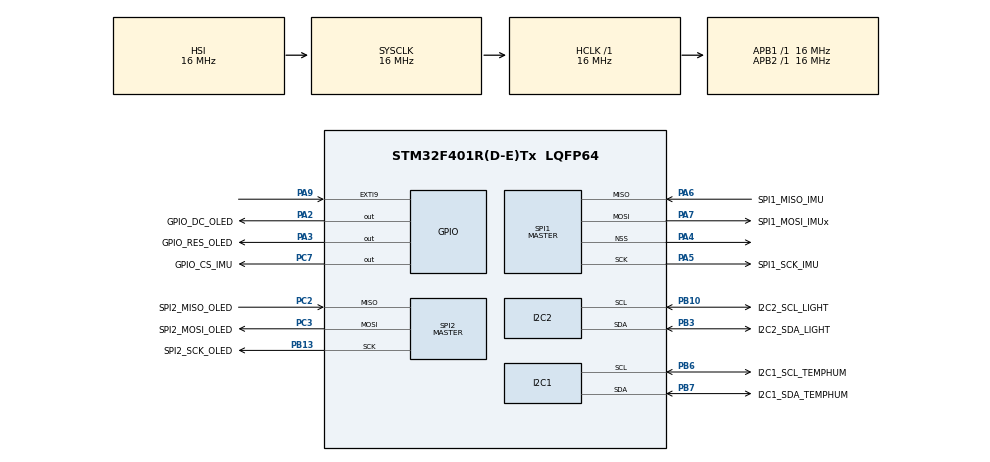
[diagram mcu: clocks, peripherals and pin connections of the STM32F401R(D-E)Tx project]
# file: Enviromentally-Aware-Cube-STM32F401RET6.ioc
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FREERTOS.Tasks01=defaultTask,24,128,StartDefaultTask,Default,NULL,Dynamic,NULL,NULL
Mcu.Family=STM32F4
Mcu.Name=STM32F401R(D-E)Tx
Mcu.Package=LQFP64
NVIC.PriorityGroup=NVIC_PRIORITYGROUP_4
PA2.GPIO_Label=GPIO_DC_OLED
PA2.Signal=GPIO_Output
PA3.GPIO_Label=GPIO_RES_OLED
PA3.Signal=GPIO_Output
PA4.Mode=NSS_Signal_Hard_Output
PA4.Signal=SPI1_NSS
PA5.GPIO_Label=SPI1_SCK_IMU
PA5.Mode=Full_Duplex_Master
PA5.Signal=SPI1_SCK
PA6.GPIO_Label=SPI1_MISO_IMU
PA6.Mode=Full_Duplex_Master
PA6.Signal=SPI1_MISO
PA7.GPIO_Label=SPI1_MOSI_IMUx
PA7.Mode=Full_Duplex_Master
PA7.Signal=SPI1_MOSI
PA9.Signal=GPXTI9
PB10.GPIO_Label=I2C2_SCL_LIGHT
PB10.Mode=I2C
PB10.Signal=I2C2_SCL
PB13.GPIO_Label=SPI2_SCK_OLED
PB13.Mode=Full_Duplex_Master
PB13.Signal=SPI2_SCK
PB3.GPIO_Label=I2C2_SDA_LIGHT
PB3.Mode=I2C
PB3.Signal=I2C2_SDA
PB6.GPIO_Label=I2C1_SCL_TEMPHUM
PB6.Mode=I2C
PB6.Signal=I2C1_SCL
PB7.GPIO_Label=I2C1_SDA_TEMPHUM
PB7.Mode=I2C
PB7.Signal=I2C1_SDA
PC2.GPIO_Label=SPI2_MISO_OLED
PC2.Mode=Full_Duplex_Master
PC2.Signal=SPI2_MISO
PC3.GPIO_Label=SPI2_MOSI_OLED
PC3.Mode=Full_Duplex_Master
PC3.Signal=SPI2_MOSI
PC7.GPIO_Label=GPIO_CS_IMU
PC7.Signal=GPIO_Output
ProjectManager.HeapSize=0x200
ProjectManager.StackSize=0x400
ProjectManager.TargetToolchain=STM32CubeIDE
RCC.AHBFreq_Value=16000000
RCC.APB1Freq_Value=16000000
RCC.APB2Freq_Value=16000000
RCC.CortexFreq_Value=16000000
RCC.HSE_VALUE=25000000
RCC.HSI_VALUE=16000000
RCC.LSE_VALUE=32768
RCC.SYSCLKFreq_VALUE=16000000
RCC.VCOOutputFreq_Value=192000000
SPI1.Direction=SPI_DIRECTION_2LINES
SPI1.Mode=SPI_MODE_MASTER
SPI1.VirtualNSS=VM_NSSHARD
SPI1.VirtualType=VM_MASTER
SPI2.Direction=SPI_DIRECTION_2LINES
SPI2.Mode=SPI_MODE_MASTER
SPI2.VirtualType=VM_MASTER
VP_FREERTOS_VS_CMSIS_V2.Mode=CMSIS_V2
board=custom

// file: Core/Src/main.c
/* USER CODE BEGIN Header */
/**
  ******************************************************************************
  * @file           : main.c
  * @brief          : Main program body
  ******************************************************************************
  * @attention
  *
  * Copyright (c) 2025 STMicroelectronics.
  * All rights reserved.
  *
  * This software is licensed under terms that can be found in the LICENSE file
  * in the root directory of this software component.
  * If no LICENSE file comes with this software, it is provided AS-IS.
  *
  ******************************************************************************
  */
/* USER CODE END Header */
#include "main.h"
#include "cmsis_os.h"

/* USER CODE BEGIN Includes */
#include "oled.h"
/* USER CODE END Includes */

I2C_HandleTypeDef hi2c1;
I2C_HandleTypeDef hi2c2;

SPI_HandleTypeDef hspi1;
SPI_HandleTypeDef hspi2;

/* Definitions for defaultTask */
osThreadId_t defaultTaskHandle;
const osThreadAttr_t defaultTask_attributes = {
  .name = "defaultTask",
  .stack_size = 128 * 4,
  .priority = (osPriority_t) osPriorityNormal,
};

void SystemClock_Config(void);
static void MX_GPIO_Init(void);
static void MX_SPI1_Init(void);
static void MX_I2C1_Init(void);
static void MX_I2C2_Init(void);
static void MX_SPI2_Init(void);
void StartDefaultTask(void *argument);

int main(void)
{

  /* MCU Configuration--------------------------------------------------------*/

  /* Reset of all peripherals, Initializes the Flash interface and the Systick. */
  HAL_Init();

  /* Configure the system clock */
  SystemClock_Config();

  /* Initialize all configured peripherals */
  MX_GPIO_Init();
  MX_SPI1_Init();
  MX_I2C1_Init();
  MX_I2C2_Init();
  MX_SPI2_Init();
  /* USER CODE BEGIN 2 */
  OLED_Init();  // Initialize the OLED display
  /* USER CODE END 2 */

  /* Init scheduler */
  osKernelInitialize();

  /* Create the thread(s) */
  /* creation of defaultTask */
  defaultTaskHandle = osThreadNew(StartDefaultTask, NULL, &defaultTask_attributes);

  /* Start scheduler */
  osKernelStart();

  /* We should never get here as control is now taken by the scheduler */
  /* Infinite loop */

  }
}

void SystemClock_Config(void)
{
  RCC_OscInitTypeDef RCC_OscInitStruct = {0};
  RCC_ClkInitTypeDef RCC_ClkInitStruct = {0};

  /** Configure the main internal regulator output voltage
  */
  __HAL_RCC_PWR_CLK_ENABLE();
  __HAL_PWR_VOLTAGESCALING_CONFIG(PWR_REGULATOR_VOLTAGE_SCALE2);

  /** Initializes the RCC Oscillators according to the specified parameters
  * in the RCC_OscInitTypeDef structure.
  */
  RCC_OscInitStruct.OscillatorType = RCC_OSCILLATORTYPE_HSI;
  RCC_OscInitStruct.HSIState = RCC_HSI_ON;
  RCC_OscInitStruct.HSICalibrationValue = RCC_HSICALIBRATION_DEFAULT;
  RCC_OscInitStruct.PLL.PLLState = RCC_PLL_NONE;
  if (HAL_RCC_OscConfig(&RCC_OscInitStruct) != HAL_OK)
  {
    Error_Handler();
  }

  /** Initializes the CPU, AHB and APB buses clocks
  */
  RCC_ClkInitStruct.ClockType = RCC_CLOCKTYPE_HCLK|RCC_CLOCKTYPE_SYSCLK
                              |RCC_CLOCKTYPE_PCLK1|RCC_CLOCKTYPE_PCLK2;
  RCC_ClkInitStruct.SYSCLKSource = RCC_SYSCLKSOURCE_HSI;
  RCC_ClkInitStruct.AHBCLKDivider = RCC_SYSCLK_DIV1;
  RCC_ClkInitStruct.APB1CLKDivider = RCC_HCLK_DIV1;
  RCC_ClkInitStruct.APB2CLKDivider = RCC_HCLK_DIV1;

  if (HAL_RCC_ClockConfig(&RCC_ClkInitStruct, FLASH_LATENCY_0) != HAL_OK)
  {
    Error_Handler();
  }
}

static void MX_I2C1_Init(void)
{

  hi2c1.Instance = I2C1;
  hi2c1.Init.ClockSpeed = 100000;
  hi2c1.Init.DutyCycle = I2C_DUTYCYCLE_2;
  hi2c1.Init.OwnAddress1 = 0;
  hi2c1.Init.AddressingMode = I2C_ADDRESSINGMODE_7BIT;
  hi2c1.Init.DualAddressMode = I2C_DUALADDRESS_DISABLE;
  hi2c1.Init.OwnAddress2 = 0;
  hi2c1.Init.GeneralCallMode = I2C_GENERALCALL_DISABLE;
  hi2c1.Init.NoStretchMode = I2C_NOSTRETCH_DISABLE;
  if (HAL_I2C_Init(&hi2c1) != HAL_OK)
  {
    Error_Handler();
  }

}

static void MX_I2C2_Init(void)
{

  hi2c2.Instance = I2C2;
  hi2c2.Init.ClockSpeed = 100000;
  hi2c2.Init.DutyCycle = I2C_DUTYCYCLE_2;
  hi2c2.Init.OwnAddress1 = 0;
  hi2c2.Init.AddressingMode = I2C_ADDRESSINGMODE_7BIT;
  hi2c2.Init.DualAddressMode = I2C_DUALADDRESS_DISABLE;
  hi2c2.Init.OwnAddress2 = 0;
  hi2c2.Init.GeneralCallMode = I2C_GENERALCALL_DISABLE;
  hi2c2.Init.NoStretchMode = I2C_NOSTRETCH_DISABLE;
  if (HAL_I2C_Init(&hi2c2) != HAL_OK)
  {
    Error_Handler();
  }

}

static void MX_SPI1_Init(void)
{

  /* SPI1 parameter configuration*/
  hspi1.Instance = SPI1;
  hspi1.Init.Mode = SPI_MODE_MASTER;
  hspi1.Init.Direction = SPI_DIRECTION_2LINES;
  hspi1.Init.DataSize = SPI_DATASIZE_8BIT;
  hspi1.Init.CLKPolarity = SPI_POLARITY_LOW;
  hspi1.Init.CLKPhase = SPI_PHASE_1EDGE;
  hspi1.Init.NSS = SPI_NSS_HARD_OUTPUT;
  hspi1.Init.BaudRatePrescaler = SPI_BAUDRATEPRESCALER_2;
  hspi1.Init.FirstBit = SPI_FIRSTBIT_MSB;
  hspi1.Init.TIMode = SPI_TIMODE_DISABLE;
  hspi1.Init.CRCCalculation = SPI_CRCCALCULATION_DISABLE;
  hspi1.Init.CRCPolynomial = 10;
  if (HAL_SPI_Init(&hspi1) != HAL_OK)
  {
    Error_Handler();
  }

}

static void MX_SPI2_Init(void)
{

  /* SPI2 parameter configuration*/
  hspi2.Instance = SPI2;
  hspi2.Init.Mode = SPI_MODE_MASTER;
  hspi2.Init.Direction = SPI_DIRECTION_2LINES;
  hspi2.Init.DataSize = SPI_DATASIZE_8BIT;
  hspi2.Init.CLKPolarity = SPI_POLARITY_LOW;
  hspi2.Init.CLKPhase = SPI_PHASE_1EDGE;
  hspi2.Init.NSS = SPI_NSS_SOFT;
  hspi2.Init.BaudRatePrescaler = SPI_BAUDRATEPRESCALER_2;
  hspi2.Init.FirstBit = SPI_FIRSTBIT_MSB;
  hspi2.Init.TIMode = SPI_TIMODE_DISABLE;
  hspi2.Init.CRCCalculation = SPI_CRCCALCULATION_DISABLE;
  hspi2.Init.CRCPolynomial = 10;
  if (HAL_SPI_Init(&hspi2) != HAL_OK)
  {
    Error_Handler();
  }

}

static void MX_GPIO_Init(void)
{
  GPIO_InitTypeDef GPIO_InitStruct = {0};

  /* GPIO Ports Clock Enable */
  __HAL_RCC_GPIOC_CLK_ENABLE();
  __HAL_RCC_GPIOA_CLK_ENABLE();
  __HAL_RCC_GPIOB_CLK_ENABLE();

  /*Configure GPIO pin Output Level */
  HAL_GPIO_WritePin(GPIOA, GPIO_DC_OLED_Pin|GPIO_RES_OLED_Pin, GPIO_PIN_RESET);

  /*Configure GPIO pin Output Level */
  HAL_GPIO_WritePin(GPIO_CS_IMU_GPIO_Port, GPIO_CS_IMU_Pin, GPIO_PIN_RESET);

  /*Configure GPIO pins : GPIO_DC_OLED_Pin GPIO_RES_OLED_Pin */
  GPIO_InitStruct.Pin = GPIO_DC_OLED_Pin|GPIO_RES_OLED_Pin;
  GPIO_InitStruct.Mode = GPIO_MODE_OUTPUT_PP;
  GPIO_InitStruct.Pull = GPIO_NOPULL;
  GPIO_InitStruct.Speed = GPIO_SPEED_FREQ_LOW;
  HAL_GPIO_Init(GPIOA, &GPIO_InitStruct);

  /*Configure GPIO pin : GPIO_CS_IMU_Pin */
  GPIO_InitStruct.Pin = GPIO_CS_IMU_Pin;
  GPIO_InitStruct.Mode = GPIO_MODE_OUTPUT_PP;
  GPIO_InitStruct.Pull = GPIO_NOPULL;
  GPIO_InitStruct.Speed = GPIO_SPEED_FREQ_LOW;
  HAL_GPIO_Init(GPIO_CS_IMU_GPIO_Port, &GPIO_InitStruct);

  /*Configure GPIO pin : PA9 */
  GPIO_InitStruct.Pin = GPIO_PIN_9;
  GPIO_InitStruct.Mode = GPIO_MODE_IT_RISING;
  GPIO_InitStruct.Pull = GPIO_NOPULL;
  HAL_GPIO_Init(GPIOA, &GPIO_InitStruct);

}

void StartDefaultTask(void *argument)
{
  for(;;)
  {
    osDelay(1);
  }
}

void Error_Handler(void)
{
  __disable_irq();
  while (1)
  {
  }
}
